# STM32WBA65xx register map
File version: 1.0
Registers are 32-bit, read-write, reset 0x0 unless marked. A register's access mark holds for its fields unless they carry their own. Offsets are from the block's base; [hi:lo] are bit positions; {n}, {i} and the like mark numbered series; 'fields as' and 'values as' point back to an identical list.

## PWR — Power Control
Base 0x46020800
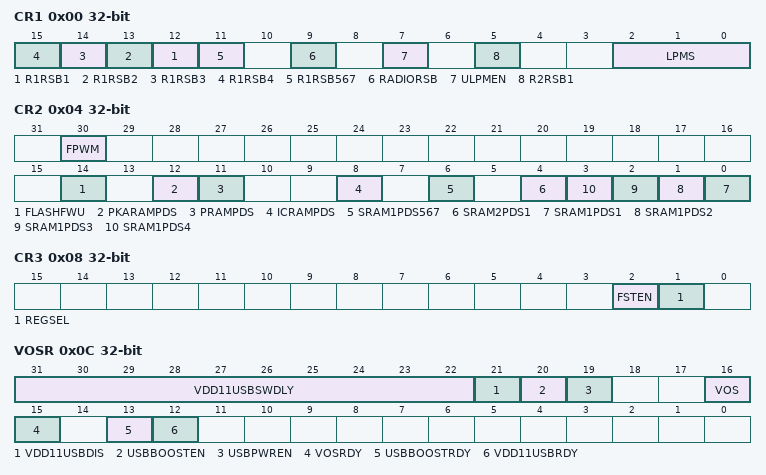
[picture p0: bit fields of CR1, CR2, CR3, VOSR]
0x00 CR1 — PWR power control register 1
  [n+11] R1RSB{n} (n=1..4) — SRAM1 Page {n} Retention in Standby
  [11] R1RSB567 — SRAM1 Pages 5-6-7 Retention in Standby
  [9] RADIORSB — 2.4GHz RADIO SRAMs (TXRX and Sequence) and Sleep clock retention in Standby mode
    0=NO_RETENTION (2.4 GHz RADIO SRAMs and sleep timer content not retained in Standby mode); 1=FULL_RETENTION (2.4 GHz RADIO SRAMs and sleep timer content retained in Standby mode)
  [7] ULPMEN — BOR ultra-low power mode in Standby/Shutdown
  [5] R2RSB1 — SRAM2 Retention in Standby
  [2:0] LPMS — LPMS[2:0] Low-power mode selection field
    0=STOP0 (Stop 0 mode); 1=STOP1 (Stop 1 mode); 2=STOP2 (Stop 2 mode); 4=STANDBY (Standby mode)
0x04 CR2 — PWR power control register 2
  [30] FPWM — SMPS PWM mode
  [14] FLASHFWU — Flash low-power mode in Stop modes
  [12] PKARAMPDS — PKA SRAM power-down in Stop modes
    0=NO_RETENTION (PKA SRAM no retention in Stop mode); 1=FULL_RETENTION (PKA SRAM full retention in Stop mode)
  [11] PRAMPDS — USB OTG_HS SRAM power-down in Stop modes
    0=NO_RETENTION (USB_OTG_HS SRAM no retention in Stop mode); 1=FULL_RETENTION (USB_OTG_HS SRAM full retention in Stop mode)
  [8] ICRAMPDS — ICACHE SRAM power-down in Stop modes
    0=NO_RETENTION (ICACHE SRAM no retention in Stop mode); 1=FULL_RETENTION (ICACHE SRAM full retention in Stop mode)
  [6] SRAM1PDS567 — SRAM1 Page 5-6-7 power-down in Stop modes
  [4] SRAM2PDS1 — SRAM2 power-down in Stop modes
  [n-1] SRAM1PDS{n} (n=1..4) — SRAM1 Page {n} power-down in Stop modes
0x08 CR3 — PWR power control register 3
  [2] FSTEN — Fast soft start
  [1] REGSEL — Regulator selection
    0=LDO_SUPPLY (LDO regulator supply); 1=SMPS_SUPPLY (SMPS regulator supply)
0x0C VOSR — PWR voltage scaling register
  [31:22] VDD11USBSWDLY — VDD11USBSWDLY[9:0] USB OTG_HS VDD11USB switch delay
  [21] VDD11USBDIS — USB OTG_HS VDD11USB disable
  [20] USBBOOSTEN — USB OTG_HS booster enable
  [19] USBPWREN — USB OTG_HS power enable
  [16] VOS — Voltage scaling range selection
    1=SCALE1 (Voltage scaling range 1 (highest frequency)); 0=SCALE2 (Voltage scaling range 2 (lowest power))
  [15] VOSRDY — Ready bit for VCORE voltage scaling output selection
  [13] USBBOOSTRDY — USB OTG_HS booster ready
  [12] VDD11USBRDY — USB OTG_HS VDD11 ready
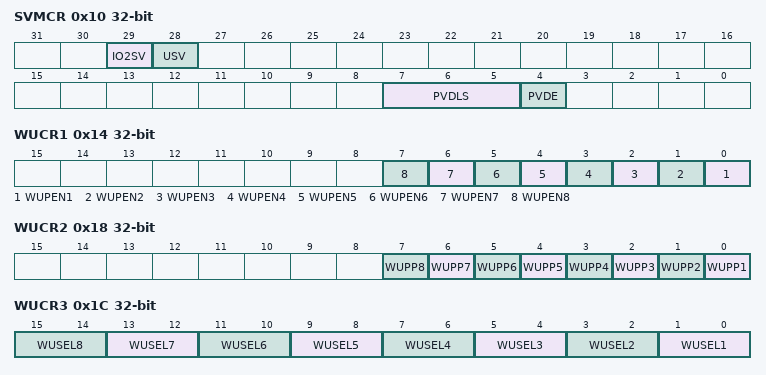
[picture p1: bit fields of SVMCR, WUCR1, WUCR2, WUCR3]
0x10 SVMCR — PWR supply voltage monitoring control register
  [29] IO2SV — VDDIO2 supply valid
  [28] USV — VDDUSB supply valid
  [7:5] PVDLS — PVDLS[2:0] Power voltage detector level selection field
    0=PVDLEVEL_0 (Voltage threshold detected by PVD 2.0 V); 1=PVDLEVEL_1 (Voltage threshold detected by PVD 2.2 V); 2=PVDLEVEL_2 (Voltage threshold detected by PVD 2.4 V); 3=PVDLEVEL_3 (Voltage threshold detected by PVD 2.5 V); 4=PVDLEVEL_4 (Voltage threshold detected by PVD 2.6 V); 5=PVDLEVEL_5 (Voltage threshold detected by PVD 2.8 V); 6=PVDLEVEL_6 (Voltage threshold detected by PVD 2.9 V); 7=PVDLEVEL_7
  [4] PVDE — Power voltage detector enable
0x14 WUCR1 — PWR wakeup control register 1
  [n-1] WUPEN{n} (n=1..8) — Wakeup pin WKUP{n} enable
0x18 WUCR2 — PWR wakeup control register 2
  [n-1] WUPP{n} (n=1..8) — Wakeup pin WKUP{n} polarity
0x1C WUCR3 — PWR wakeup control register 3
  [2n-1:2n-2] WUSEL{n} (n=1..8) — Wakeup pin WKUP{n} selection field
0x28 DBPR — PWR disable backup domain register
  [0] DBP — Disable backup domain write protection
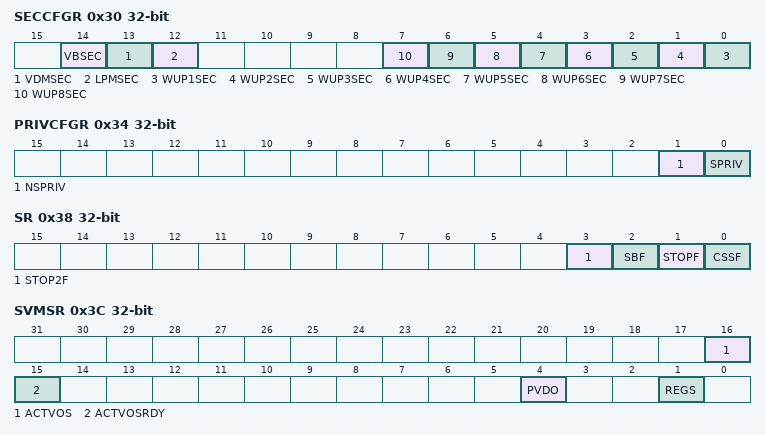
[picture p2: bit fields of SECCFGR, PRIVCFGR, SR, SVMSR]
0x30 SECCFGR — PWR Security configuration register
  [14] VBSEC — Backup domain secure protection
  [13] VDMSEC — Voltage detection and monitoring secure protection
  [12] LPMSEC — Low-power modes secure protection
  [n-1] WUP{n}SEC (n=1..8) — WUP{n} secure protection
0x34 PRIVCFGR — PWR privilege control register
  [1] NSPRIV — RCC non-secure functions privilege configuration
  [0] SPRIV — RCC secure functions privilege configuration
0x38 SR — PWR status register
  [3] STOP2F — Stop 2 flag
  [2] SBF — Standby/Shutdown flag
  [1] STOPF — Stop flag
  [0] CSSF — Clear Stop and Standby/Shutdown flags
0x3C SVMSR — PWR supply voltage monitoring status register
  [16] ACTVOS — Voltage Output Scaling currently applied to VCORE
    values as VOSR.VOS
  [15] ACTVOSRDY — Voltage level ready for currently used VOS
  [4] PVDO — VDD voltage detector output
  [1] REGS — Regulator status
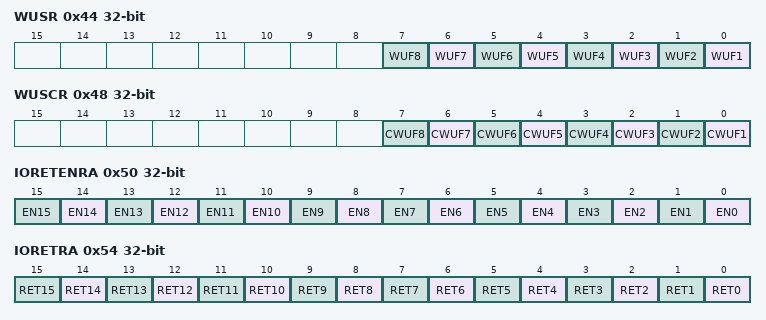
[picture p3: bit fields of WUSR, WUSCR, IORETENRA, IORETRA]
0x44 WUSR — PWR wakeup status register
  [n-1] WUF{n} (n=1..8) — Wakeup flag {n}
0x48 WUSCR — PWR wakeup status clear register
  [n-1] CWUF{n} (n=1..8) — Wakeup clear flag {n}
0x4C APCR — PWR apply pull configuration register
0x50 IORETENRA — PWR Port A IO retention in Standby register
  [n] EN{n} (n=0..15) — Standby GPIO retention enable for PA{n}
0x54 IORETRA — PWR Port A IO retention status in Standby register
  [n] RET{n} (n=0..15) — Standby GPIO retention status for PA{n}
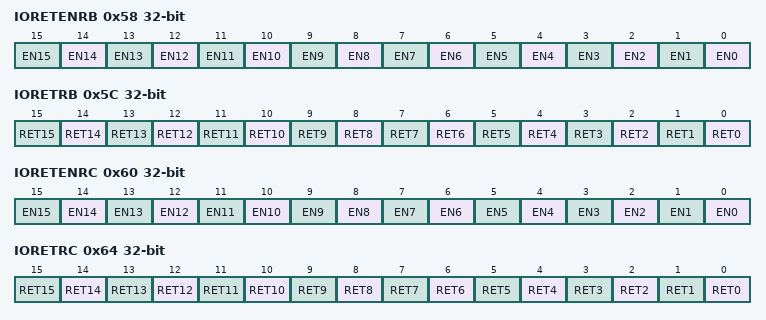
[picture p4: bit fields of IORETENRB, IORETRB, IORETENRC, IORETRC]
0x58 IORETENRB — PWR Port B IO retention in Standby register
  [n] EN{n} (n=0..15) — Standby GPIO retention enable for PB{n}
0x5C IORETRB — PWR Port B IO retention status in Standby register
  [n] RET{n} (n=0..15) — Standby GPIO retention status for PB{n}
0x60 IORETENRC — PWR Port C IO retention in Standby register
  [n] EN{n} (n=0..15) — Standby GPIO retention enable for PC{n}
0x64 IORETRC — PWR Port C IO retention status in Standby register
  [n] RET{n} (n=0..15) — Standby GPIO retention status for PC{n}
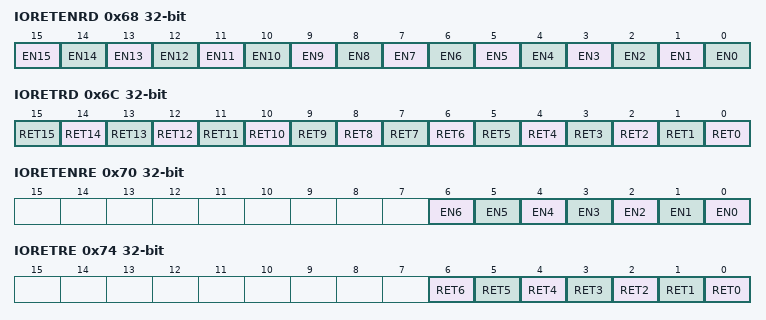
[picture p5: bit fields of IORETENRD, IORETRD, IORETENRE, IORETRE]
0x68 IORETENRD — PWR Port D IO retention in Standby register
  [15] EN15 — Standby GPIO retention enable for PD14
  [n] EN{n} (n=0..14) — Standby GPIO retention enable for PD{n}
0x6C IORETRD — PWR Port D IO retention status in Standby register
  [n] RET{n} (n=0..15) — Standby GPIO retention status for PD{n}
0x70 IORETENRE — PWR Port E IO retention in Standby register
  [n] EN{n} (n=0..6) — Standby GPIO retention enable for PE{n}
0x74 IORETRE — PWR Port E IO retention status in Standby register
  [n] RET{n} (n=0..6) — Standby GPIO retention status for PE{n}
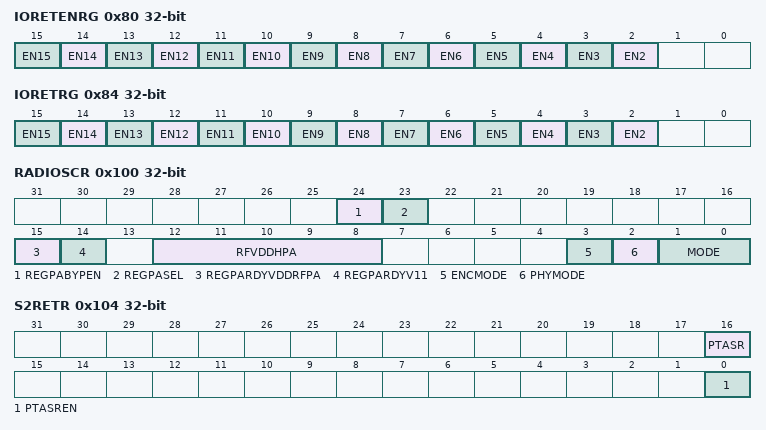
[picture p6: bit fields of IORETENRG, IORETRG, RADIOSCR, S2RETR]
0x80 IORETENRG — PWR Port G IO retention in Standby register
  [n] EN{n} (n=2..15) — Standby GPIO retention enable for PG{n}
0x84 IORETRG — PWR Port G IO retention status in Standby register
  [n] EN{n} (n=2..15) — Standby GPIO retention status for PG{n}
0x88 IORETENRH — PWR Port H IO retention in Standby register
  [3] EN3 — Standby GPIO retention enable for PH3
0x8C IORETRH — PWR Port H IO retention status in Standby register
  [3] RET3 — Standby GPIO retention status for PH3
0x100 RADIOSCR — PWR 2.4 GHZ radio status and control register
  [24] REGPABYPEN — Regulator REG_VDDHPA bypass enable
  [23] REGPASEL — Regulator REG_VDDHPA input supply selection
    0=PIN (VDDRFPA pin selected as regulator REG_VDDHPA input supply); 1=VDD11 (Regulator REG_VDDHPA input supply selection between VDDRFPA and VDD11 dependent on requested regulated output voltage)
  [15] REGPARDYVDDRFPA — Ready bit for VDDHPA voltage level when selecting VDDRFPA input
  [14] REGPARDYV11 — Ready bit for VDDHPA voltage level when selecting VDDRFPA input
  [12:8] RFVDDHPA — 2.4 GHz RADIO VDDHPA control word
  [3] ENCMODE — 2.4 GHz RADIO encryption function operating mode
  [2] PHYMODE — 2.4 GHz RADIO PHY operating mode
    0=SLEEP_MODE (2.4 GHz RADIO Sleep mode); 1=STANDBY_MODE (2.4 GHz RADIO Standby mode)
  [1:0] MODE — 2.4 GHz RADIO operating mode
0x104 S2RETR — PWR Stop 2 peripheral IOs retention register
  [16] PTASR — PTA interface output signals state retention in Stop 2 mode active
  [0] PTASREN — PTA output signals Stop 2 mode retention enable
